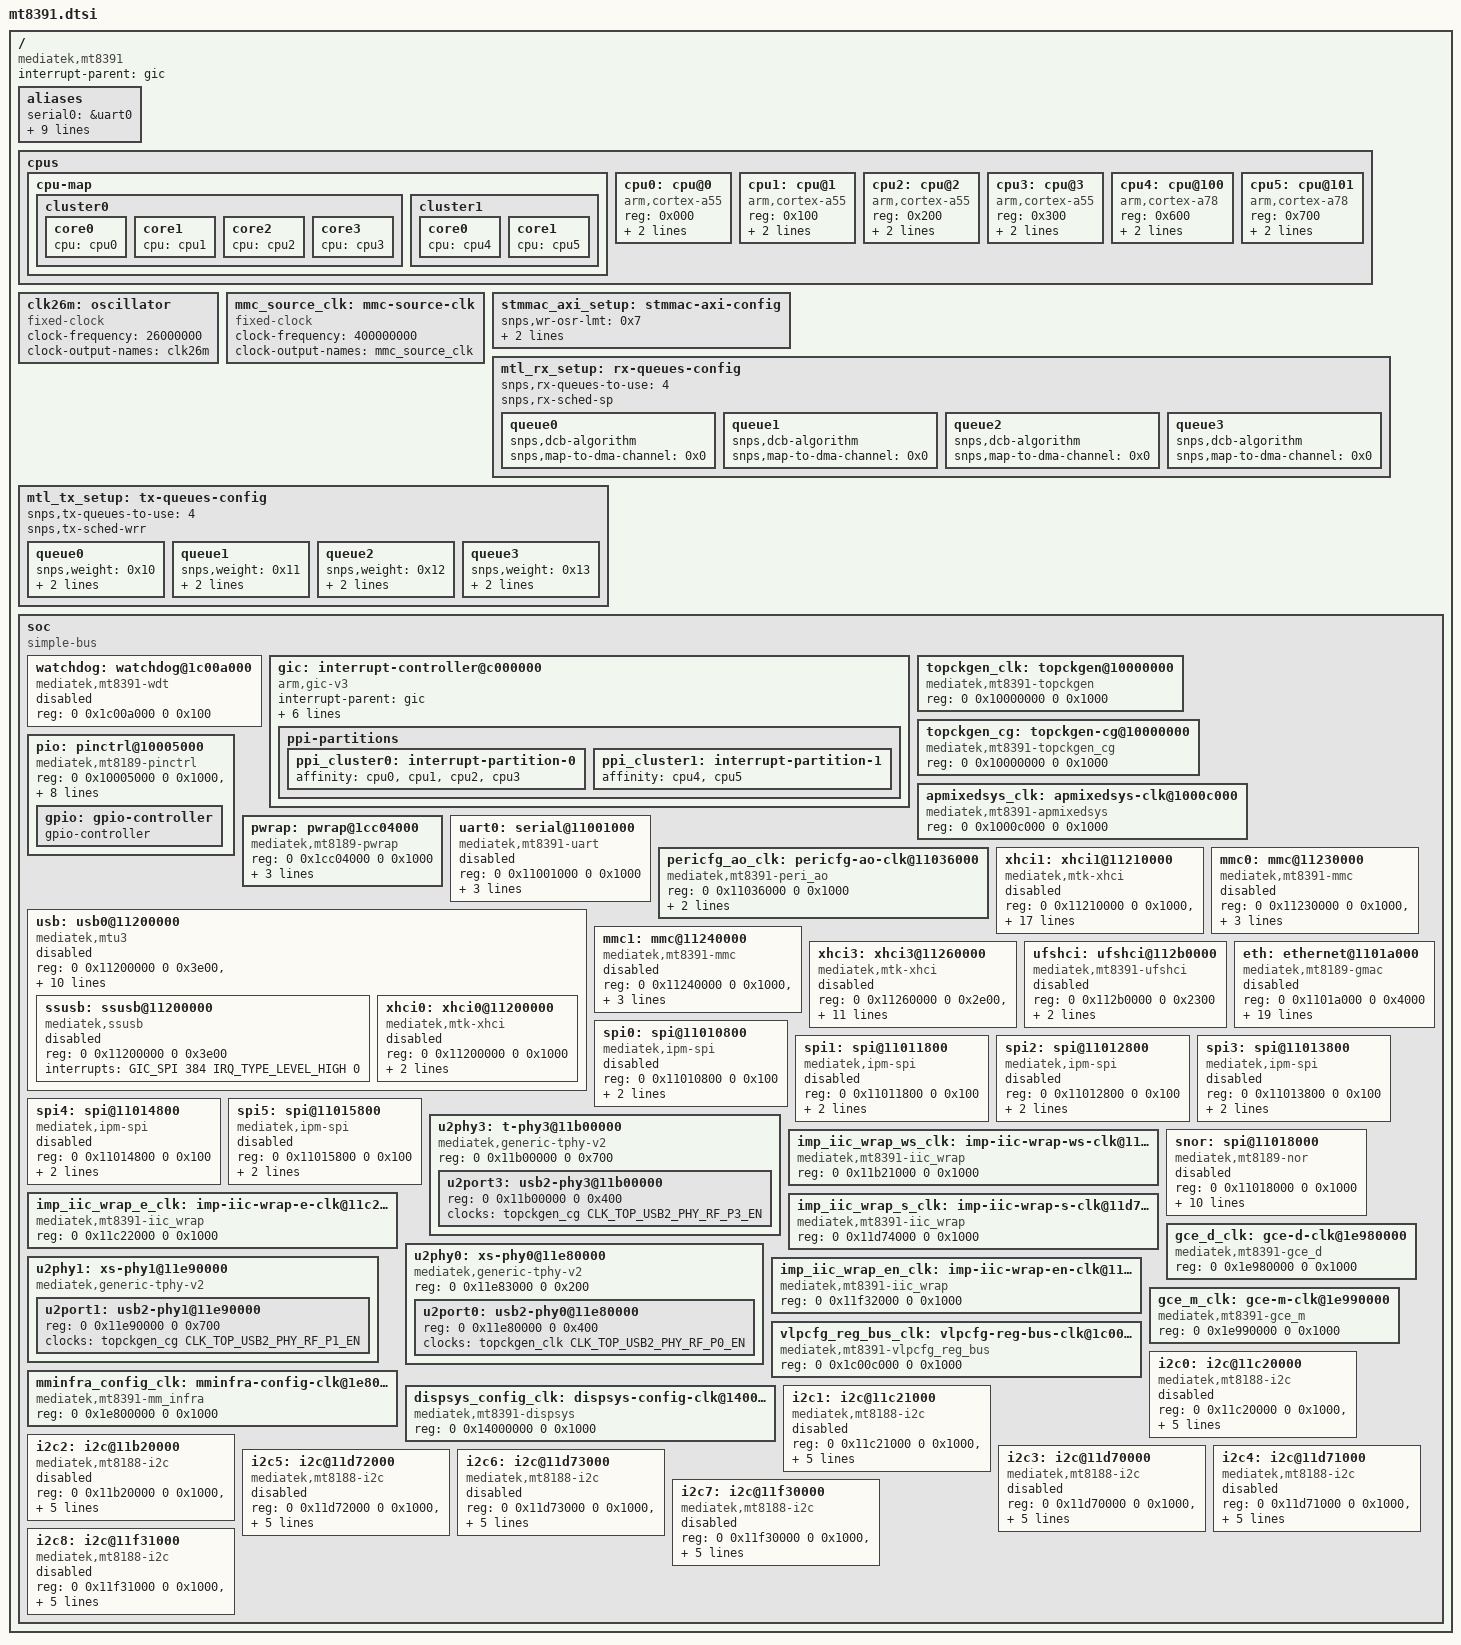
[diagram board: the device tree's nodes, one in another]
// SPDX-License-Identifier: (GPL-2.0 OR MIT)
/*
 * Copyright (C) 2023 MediaTek Inc.
 * Author: Macpaul Lin <macpaul.lin@mediatek.com>
 */

#include <dt-bindings/gpio/gpio.h>
#include <dt-bindings/interrupt-controller/irq.h>
#include <dt-bindings/interrupt-controller/arm-gic.h>
#include <dt-bindings/pinctrl/mediatek,mt8189-pinfunc.h>
#include <dt-bindings/phy/phy.h>
#include <dt-bindings/clock/mt8391-clk.h>

/ {
	compatible = "mediatek,mt8391";
	interrupt-parent = <&gic>;
	#address-cells = <2>;
	#size-cells = <2>;

	aliases {
		serial0 = &uart0;
		i2c0 = &i2c0;
		i2c1 = &i2c1;
		i2c2 = &i2c2;
		i2c3 = &i2c3;
		i2c4 = &i2c4;
		i2c5 = &i2c5;
		i2c6 = &i2c6;
		i2c7 = &i2c7;
		i2c8 = &i2c8;
	};

	cpus {
		#address-cells = <1>;
		#size-cells = <0>;

		cpu-map {
			cluster0 {
				core0 {
					cpu = <&cpu0>;
				};
				core1 {
					cpu = <&cpu1>;
				};
				core2 {
					cpu = <&cpu2>;
				};
				core3 {
					cpu = <&cpu3>;
				};
			};
			cluster1 {
				core0 {
					cpu = <&cpu4>;
				};
				core1 {
					cpu = <&cpu5>;
				};
			};
		};

		cpu0: cpu@0 {
			device_type = "cpu";
			compatible = "arm,cortex-a55", "arm,armv8";
			reg = <0x000>;
			enable-method = "psci";
			capacity-dmips-mhz = <282>;
		};

		cpu1: cpu@1 {
			device_type = "cpu";
			compatible = "arm,cortex-a55", "arm,armv8";
			reg = <0x100>;
			enable-method = "psci";
			capacity-dmips-mhz = <282>;
		};

		cpu2: cpu@2 {
			device_type = "cpu";
			compatible = "arm,cortex-a55", "arm,armv8";
			reg = <0x200>;
			enable-method = "psci";
			capacity-dmips-mhz = <282>;
		};

		cpu3: cpu@3 {
			device_type = "cpu";
			compatible = "arm,cortex-a55", "arm,armv8";
			reg = <0x300>;
			enable-method = "psci";
			capacity-dmips-mhz = <282>;
		};

		cpu4: cpu@100 {
			device_type = "cpu";
			compatible = "arm,cortex-a78", "arm,armv8";
			reg = <0x600>;
			enable-method = "psci";
			capacity-dmips-mhz = <1024>;
		};

		cpu5: cpu@101 {
			device_type = "cpu";
			compatible = "arm,cortex-a78", "arm,armv8";
			reg = <0x700>;
			enable-method = "psci";
			capacity-dmips-mhz = <1024>;
		};
	};

	clk26m: oscillator {
		compatible = "fixed-clock";
		#clock-cells = <0>;
		clock-frequency = <26000000>;
		clock-output-names = "clk26m";
	};

	mmc_source_clk: mmc-source-clk{
		compatible = "fixed-clock";
		#clock-cells = <0>;
		clock-frequency = <400000000>;
		clock-output-names = "mmc_source_clk";
	};

	stmmac_axi_setup: stmmac-axi-config {
		snps,wr-osr-lmt = <0x7>;
		snps,rd-osr-lmt = <0x7>;
		snps,blen = <0 0 0 0 16 8 4>;
	};

	mtl_rx_setup: rx-queues-config {
		snps,rx-queues-to-use = <4>;
		snps,rx-sched-sp;
		queue0 {
			snps,dcb-algorithm;
			snps,map-to-dma-channel = <0x0>;
		};
		queue1 {
			snps,dcb-algorithm;
			snps,map-to-dma-channel = <0x0>;
		};
		queue2 {
			snps,dcb-algorithm;
			snps,map-to-dma-channel = <0x0>;
		};
		queue3 {
			snps,dcb-algorithm;
			snps,map-to-dma-channel = <0x0>;
		};
	};

	mtl_tx_setup: tx-queues-config {
		snps,tx-queues-to-use = <4>;
		snps,tx-sched-wrr;
		queue0 {
			snps,weight = <0x10>;
			snps,dcb-algorithm;
			snps,priority = <0x0>;
		};
		queue1 {
			snps,weight = <0x11>;
			snps,dcb-algorithm;
			snps,priority = <0x1>;
		};
		queue2 {
			snps,weight = <0x12>;
			snps,dcb-algorithm;
			snps,priority = <0x2>;
		};
		queue3 {
			snps,weight = <0x13>;
			snps,dcb-algorithm;
			snps,priority = <0x3>;
		};
	};

	soc {
		#address-cells = <2>;
		#size-cells = <2>;
		compatible = "simple-bus";
		ranges;

		watchdog: watchdog@1c00a000 {
			compatible = "mediatek,mt8391-wdt",
				     "mediatek,wdt";
			reg = <0 0x1c00a000 0 0x100>;
			status = "disabled";
		};

		gic: interrupt-controller@c000000 {
			compatible = "arm,gic-v3";
			#interrupt-cells = <4>;
			interrupt-parent = <&gic>;
			interrupt-controller;
			reg = <0 0x0c000000 0 0x40000>,  /* GICD */
			      <0 0x0c100000 0 0x200000>, /* GICR */
			      <0 0x0c400000 0 0x2000>,   /* GICC */
			      <0 0x0c410000 0 0x1000>,   /* GICH */
			      <0 0x0c420000 0 0x2000>;   /* GICV */

			interrupts = <GIC_PPI 9 IRQ_TYPE_LEVEL_HIGH 0>;
			ppi-partitions {
				ppi_cluster0: interrupt-partition-0 {
					affinity = <&cpu0 &cpu1 &cpu2 &cpu3>;
				};
				ppi_cluster1: interrupt-partition-1 {
					affinity = <&cpu4 &cpu5>;
				};
			};
		};

		topckgen_clk: topckgen@10000000 {
			compatible = "mediatek,mt8391-topckgen";
			reg = <0 0x10000000 0 0x1000>;
			#clock-cells = <1>;
		};

		topckgen_cg: topckgen-cg@10000000 {
			compatible = "mediatek,mt8391-topckgen_cg";
			reg = <0 0x10000000 0 0x1000>;
			#clock-cells = <1>;
		};

		apmixedsys_clk: apmixedsys-clk@1000c000 {
			compatible = "mediatek,mt8391-apmixedsys";
			reg = <0 0x1000c000 0 0x1000>;
			#clock-cells = <1>;
		};

		pio: pinctrl@10005000 {
			compatible = "mediatek,mt8189-pinctrl";
			reg = <0 0x10005000 0 0x1000>,
				<0 0x11d20000 0 0x1000>,
				<0 0x11d30000 0 0x1000>,
				<0 0x11d40000 0 0x1000>,
				<0 0x11b50000 0 0x1000>,
				<0 0x11e20000 0 0x1000>,
				<0 0x11e30000 0 0x1000>,
				<0 0x11c50000 0 0x1000>,
				<0 0x11c60000 0 0x1000>,
				<0 0x11f20000 0 0x1000>;
			reg-names = "gpio_base",
				"iocfg_bm0_base",
				"iocfg_bm1_base",
				"iocfg_bm2_base",
				"iocfg_lm_base",
				"iocfg_lt0_base",
				"iocfg_lt1_base",
				"iocfg_rb0_base",
				"iocfg_rb1_base",
				"iocfg_rt_base";
			gpio: gpio-controller {
				gpio-controller;
				#gpio-cells = <2>;
			};
		};

		pwrap: pwrap@1cc04000 {
			compatible = "mediatek,mt8189-pwrap";
			reg = <0 0x1cc04000 0 0x1000>;
			clocks =  <&vlpcfg_reg_bus_clk CLK_VLPCFG_REG_PMIF_SPMI_M_SYS>,
				<&vlpcfg_reg_bus_clk CLK_VLPCFG_REG_PMIF_SPMI_M_TMR>;
			clock-names = "spi", "wrap";
		};

		uart0: serial@11001000 {
			compatible = "mediatek,mt8391-uart",
				     "mediatek,hsuart";
			reg = <0 0x11001000 0 0x1000>;
			interrupts = <GIC_SPI 91 IRQ_TYPE_LEVEL_LOW>;
			clock-frequency = <26000000>;
			clocks = <&clk26m>, <&clk26m>;
			clock-names = "baud", "bus";
			status = "disabled";
		};

		pericfg_ao_clk: pericfg-ao-clk@11036000 {
			compatible = "mediatek,mt8391-peri_ao", "syscon";
			reg = <0 0x11036000 0 0x1000>;
			#clock-cells = <1>;
			clocks = <&topckgen_clk>;
			clock-output-names = "pericfg_ao_clk";
		};

		usb: usb0@11200000 {
			compatible = "mediatek,mtu3";
			reg = <0 0x11200000 0 0x3e00>,
			      <0 0x11203e00 0 0x0100>;
			reg-names = "mac", "ippc";
			phy-cells = <1>;
			phys = <&u2port0 PHY_TYPE_USB2>;
			mediatek,u3p-dis-msk = <0x1>;
			clocks = <&pericfg_ao_clk CLK_PERAO_SSUSB0_XHCI>,
				 <&pericfg_ao_clk CLK_PERAO_SSUSB0_SYS>,
				 <&pericfg_ao_clk CLK_PERAO_SSUSB0_H>,
				 <&pericfg_ao_clk CLK_PERAO_SSUSB0_F>,
				 <&pericfg_ao_clk CLK_PERAO_SSUSB0_REF>,
				 <&pericfg_ao_clk CLK_PERAO_SSUSB0_FRMCNT>;
			clock-names = "host_ck",
				      "sys_ck",
				      "mcu_ck",
				      "dma_ck",
				      "ref_ck",
				      "frmcnt_ck";
			#address-cells = <2>;
			#size-cells = <2>;
			ranges;
			status = "disabled";

			ssusb: ssusb@11200000 {
				compatible = "mediatek,ssusb";
				reg = <0 0x11200000 0 0x3e00>;
				reg-names = "mac";
				interrupts = <GIC_SPI 384 IRQ_TYPE_LEVEL_HIGH 0>;
				status = "disabled";
			};

			xhci0: xhci0@11200000 {
				compatible = "mediatek,mtk-xhci";
				reg = <0 0x11200000 0 0x1000>;
				reg-names = "mac";
				interrupts = <GIC_SPI 385 IRQ_TYPE_LEVEL_HIGH 0>;
				clocks = <&pericfg_ao_clk CLK_PERAO_SSUSB0_XHCI>;
				clock-names = "xhci_ck";
				status = "disabled";
			};
		};

		xhci1: xhci1@11210000 {
			compatible = "mediatek,mtk-xhci";
			reg = <0 0x11210000 0 0x1000>,
			      <0 0x11213e00 0 0x0100>;
			reg-names = "mac", "ippc";
			interrupts = <GIC_SPI 386 IRQ_TYPE_LEVEL_HIGH 0>;
			phy-cells = <1>;
			phys = <&u2port1 PHY_TYPE_USB2>;
			assigned-clocks = <&topckgen_clk CLK_TOP_USB_TOP_P1_SEL>,
					  <&topckgen_clk CLK_TOP_USB_XHCI_P1_SEL>;
			assigned-clock-parents = <&topckgen_clk CLK_TOP_UNIVPLL_D5_D4>,
						 <&topckgen_clk CLK_TOP_UNIVPLL_D5_D4>;
			clocks = <&pericfg_ao_clk CLK_PERAO_SSUSB1_XHCI>,
				 <&pericfg_ao_clk CLK_PERAO_SSUSB1_SYS>,
				 <&pericfg_ao_clk CLK_PERAO_SSUSB1_H>,
				 <&pericfg_ao_clk CLK_PERAO_SSUSB1_F>,
				 <&pericfg_ao_clk CLK_PERAO_SSUSB1_REF>,
				 <&pericfg_ao_clk CLK_PERAO_SSUSB1_FRMCNT>;
			clock-names = "xhci_ck",
				      "sys_ck",
				      "mcu_ck",
				      "dma_ck",
				      "ref_ck",
				      "frmcnt_ck";
			maximum-speed = "high-speed";
			status = "disabled";
		};

		mmc0: mmc@11230000 {
			compatible = "mediatek,mt8391-mmc",
				     "mediatek,mt8183-mmc";
			reg = <0 0x11230000 0 0x1000>,
			      <0 0x11e70000 0 0x1000>;
			interrupts = <GIC_SPI 387 IRQ_TYPE_LEVEL_HIGH 0>;
			clocks = <&mmc_source_clk>,
				 <&clk26m>,
				 <&clk26m>;
			clock-names = "source", "hclk", "source_cg";
			status = "disabled";
		};

		mmc1: mmc@11240000 {
			compatible = "mediatek,mt8391-mmc",
				     "mediatek,mt8183-mmc";
			reg = <0 0x11240000 0 0x1000>,
			      <0 0x11d80000 0 0x1000>;
			interrupts = <GIC_SPI 388 IRQ_TYPE_LEVEL_HIGH 0>;
			clocks = <&mmc_source_clk>,
				 <&clk26m>,
				 <&clk26m>;
			clock-names = "source", "hclk", "source_cg";
			status = "disabled";
		};

		xhci3: xhci3@11260000 {
			compatible = "mediatek,mtk-xhci";
			reg = <0 0x11260000 0 0x2e00>,
			      <0 0x11263e00 0 0x0100>;
			reg-names = "mac", "ippc";
			interrupts = <GIC_SPI 473 IRQ_TYPE_LEVEL_HIGH 0>;
			phy-cells = <1>;
			phys = <&u2port3 PHY_TYPE_USB2>;
			mediatek,u3p-dis-msk = <0x1>;
			clocks = <&pericfg_ao_clk CLK_PERAO_SSUSB3_XHCI>,
				 <&pericfg_ao_clk CLK_PERAO_SSUSB3_SYS>,
				 <&pericfg_ao_clk CLK_PERAO_SSUSB3_H>,
				 <&pericfg_ao_clk CLK_PERAO_SSUSB3_F>,
				 <&pericfg_ao_clk CLK_PERAO_SSUSB3_REF>,
				 <&pericfg_ao_clk CLK_PERAO_SSUSB3_FRMCNT>;
			clock-names = "xhci_ck",
				      "sys_ck",
				      "mcu_ck",
				      "dma_ck",
				      "ref_ck",
				      "frmcnt_ck";
			status = "disabled";
		};

		ufshci: ufshci@112b0000 {
			compatible = "mediatek,mt8391-ufshci",
				     "mediatek,mt8183-ufshci";
			reg = <0 0x112b0000 0 0x2300>;
			interrupts = <GIC_SPI 393 IRQ_TYPE_LEVEL_HIGH 0>;
			clocks = <&mmc_source_clk>,
				 <&clk26m>,
				 <&clk26m>;
			clock-names = "source", "hclk", "source_cg";
			status = "disabled";
		};

		eth: ethernet@1101a000 {
			compatible = "mediatek,mt8189-gmac", "snps,dwmac-5.10a";
			reg = <0 0x1101a000 0 0x4000>;
			interrupts = <GIC_SPI 475 IRQ_TYPE_LEVEL_HIGH 0>;
			interrupt-names = "macirq";
			clock-names = "mac_main",
					"ptp_ref",
					"rmii_internal";
			clocks = <&topckgen_clk CLK_TOP_ETH_250M_SEL>,
				<&topckgen_clk CLK_TOP_ETH_62P4M_PTP_SEL>,
				<&topckgen_clk CLK_TOP_ETH_50M_RMII_SEL>;
			assigned-clocks = <&topckgen_clk CLK_TOP_ETH_250M_SEL>,
				  <&topckgen_clk CLK_TOP_ETH_62P4M_PTP_SEL>,
				  <&topckgen_clk CLK_TOP_ETH_50M_RMII_SEL>;
			assigned-clock-parents = <&topckgen_clk CLK_TOP_ETHPLL_D2>,
						<&topckgen_clk CLK_TOP_ETHPLL_D8>,
						<&topckgen_clk CLK_TOP_ETHPLL_D10>;
			mediatek,pericfg = <&pericfg_ao_clk>;
			snps,axi-config = <&stmmac_axi_setup>;
			snps,mtl-rx-config = <&mtl_rx_setup>;
			snps,mtl-tx-config = <&mtl_tx_setup>;
			snps,txpbl = <16>;
			snps,rxpbl = <16>;
			clk-csr = <4>;
			status = "disabled";
		};

		spi0: spi@11010800 {
			compatible = "mediatek,ipm-spi";
			reg = <0 0x11010800 0 0x100>;
			interrupts = <GIC_SPI 459 IRQ_TYPE_LEVEL_HIGH>;
			clocks = <&pericfg_ao_clk CLK_PERAO_SPI0_B>;
			clock-names = "spi-clk";
			status = "disabled";
		};

		spi1: spi@11011800 {
			compatible = "mediatek,ipm-spi";
			reg = <0 0x11011800 0 0x100>;
			interrupts = <GIC_SPI 460 IRQ_TYPE_LEVEL_HIGH>;
			clocks = <&pericfg_ao_clk CLK_PERAO_SPI1_B>;
			clock-names = "spi-clk";
			status = "disabled";
		};

		spi2: spi@11012800 {
			compatible = "mediatek,ipm-spi";
			reg = <0 0x11012800 0 0x100>;
			interrupts = <GIC_SPI 461 IRQ_TYPE_LEVEL_HIGH>;
			clocks = <&pericfg_ao_clk CLK_PERAO_SPI2_B>;
			clock-names = "spi-clk";
			status = "disabled";
		};

		spi3: spi@11013800 {
			compatible = "mediatek,ipm-spi";
			reg = <0 0x11013800 0 0x100>;
			interrupts = <GIC_SPI 462 IRQ_TYPE_LEVEL_HIGH>;
			clocks = <&pericfg_ao_clk CLK_PERAO_SPI3_B>;
			clock-names = "spi-clk";
			status = "disabled";
		};

		spi4: spi@11014800 {
			compatible = "mediatek,ipm-spi";
			reg = <0 0x11014800 0 0x100>;
			interrupts = <GIC_SPI 463 IRQ_TYPE_LEVEL_HIGH>;
			clocks = <&pericfg_ao_clk CLK_PERAO_SPI4_B>;
			clock-names = "spi-clk";
			status = "disabled";
		};

		spi5: spi@11015800 {
			compatible = "mediatek,ipm-spi";
			reg = <0 0x11015800 0 0x100>;
			interrupts = <GIC_SPI 464 IRQ_TYPE_LEVEL_HIGH>;
			clocks = <&pericfg_ao_clk CLK_PERAO_SPI5_B>;
			clock-names = "spi-clk";
			status = "disabled";
		};

		u2phy3: t-phy3@11b00000 {
			compatible = "mediatek,generic-tphy-v2";
			reg = <0 0x11b00000 0 0x700>;
			#address-cells = <2>;
			#size-cells = <2>;
			ranges;

			u2port3: usb2-phy3@11b00000 {
				reg = <0 0x11b00000 0 0x400>;
				clocks = <&topckgen_cg CLK_TOP_USB2_PHY_RF_P3_EN>;
				clock-names = "ref";
				#phy-cells = <1>;
			};
		};

		imp_iic_wrap_ws_clk: imp-iic-wrap-ws-clk@11b21000 {
			compatible = "mediatek,mt8391-iic_wrap";
			reg = <0 0x11b21000 0 0x1000>;
			#clock-cells = <1>;
		};

		imp_iic_wrap_e_clk: imp-iic-wrap-e-clk@11c22000 {
			compatible = "mediatek,mt8391-iic_wrap";
			reg = <0 0x11c22000 0 0x1000>;
			#clock-cells = <1>;
		};

		imp_iic_wrap_s_clk: imp-iic-wrap-s-clk@11d74000 {
			compatible = "mediatek,mt8391-iic_wrap";
			reg = <0 0x11d74000 0 0x1000>;
			#clock-cells = <1>;
		};

		u2phy0: xs-phy0@11e80000 {
			compatible = "mediatek,generic-tphy-v2";
			reg = <0 0x11e83000 0 0x200>;
			#address-cells = <2>;
			#size-cells = <2>;
			ranges;

			u2port0: usb2-phy0@11e80000 {
				reg = <0 0x11e80000 0 0x400>;
				clocks = <&topckgen_clk CLK_TOP_USB2_PHY_RF_P0_EN>;
				clock-names = "ref";
				#phy-cells = <1>;
			};
		};

		u2phy1: xs-phy1@11e90000 {
			compatible = "mediatek,generic-tphy-v2";
			#address-cells = <2>;
			#size-cells = <2>;
			ranges;

			u2port1: usb2-phy1@11e90000 {
				reg = <0 0x11e90000 0 0x700>;
				clocks = <&topckgen_cg CLK_TOP_USB2_PHY_RF_P1_EN>;
				clock-names = "ref";
				#phy-cells = <1>;
			};
		};

		snor: spi@11018000 {
			compatible = "mediatek,mt8189-nor";
			reg = <0 0x11018000 0 0x1000>;
			clocks = <&topckgen_clk CLK_TOP_SFLASH_SEL>,
				<&pericfg_ao_clk CLK_PERAO_SFLASH>,
				<&pericfg_ao_clk CLK_PERAO_SFLASH_F>,
				<&pericfg_ao_clk CLK_PERAO_SFLASH_H>,
				<&pericfg_ao_clk CLK_PERAO_SFLASH_P>;
			clock-names = "spi", "sf", "axi_f", "axi_h", "axi_p";
			assigned-clocks = <&topckgen_clk CLK_TOP_SFLASH_SEL>;
			assigned-clock-parents = <&topckgen_clk CLK_TOP_UNIVPLL_D6_D8>;
			interrupts = <GIC_SPI 390 IRQ_TYPE_LEVEL_HIGH 0>;
			#address-cells = <1>;
			#size-cells = <0>;
			status = "disabled";
		};

		imp_iic_wrap_en_clk: imp-iic-wrap-en-clk@11f32000 {
			compatible = "mediatek,mt8391-iic_wrap";
			reg = <0 0x11f32000 0 0x1000>;
			#clock-cells = <1>;
		};

		vlpcfg_reg_bus_clk: vlpcfg-reg-bus-clk@1c00c000 {
			compatible = "mediatek,mt8391-vlpcfg_reg_bus";
			reg = <0 0x1c00c000 0 0x1000>;
			#clock-cells = <1>;
		};

		mminfra_config_clk: mminfra-config-clk@1e800000 {
			compatible = "mediatek,mt8391-mm_infra";
			reg = <0 0x1e800000 0 0x1000>;
			#clock-cells = <1>;
		};

		gce_d_clk: gce-d-clk@1e980000 {
			compatible = "mediatek,mt8391-gce_d";
			reg = <0 0x1e980000 0 0x1000>;
			#clock-cells = <1>;
		};

		gce_m_clk: gce-m-clk@1e990000 {
			compatible = "mediatek,mt8391-gce_m";
			reg = <0 0x1e990000 0 0x1000>;
			#clock-cells = <1>;
		};

		dispsys_config_clk: dispsys-config-clk@14000000 {
			compatible = "mediatek,mt8391-dispsys";
			reg = <0 0x14000000 0 0x1000>;
			#clock-cells = <1>;
		};

		i2c0: i2c@11c20000 {
			compatible = "mediatek,mt8188-i2c";
			reg = <0 0x11c20000 0 0x1000>,
				<0 0x11300200 0 0x80>;
			interrupts = <GIC_SPI 274 IRQ_TYPE_LEVEL_HIGH 0>;
			clocks = <&imp_iic_wrap_e_clk CLK_IMPE_I2C0>,
				<&pericfg_ao_clk CLK_PERAO_DMA_B>;
			clock-names = "main", "dma";
			clock-div = <1>;
			#address-cells = <1>;
			#size-cells = <0>;
			status = "disabled";
		};

		i2c1: i2c@11c21000 {
			compatible = "mediatek,mt8188-i2c";
			reg = <0 0x11c21000 0 0x1000>,
				<0 0x11300300 0 0x80>;
			interrupts = <GIC_SPI 275 IRQ_TYPE_LEVEL_HIGH 0>;
			clocks = <&imp_iic_wrap_e_clk CLK_IMPE_I2C1>,
				<&pericfg_ao_clk CLK_PERAO_DMA_B>;
			clock-names = "main", "dma";
			clock-div = <1>;
			#address-cells = <1>;
			#size-cells = <0>;
			status = "disabled";
		};

		i2c2: i2c@11b20000 {
			compatible = "mediatek,mt8188-i2c";
			reg = <0 0x11b20000 0 0x1000>,
				<0 0x11300400 0 0x80>;
			interrupts = <GIC_SPI 276 IRQ_TYPE_LEVEL_HIGH 0>;
			clocks = <&imp_iic_wrap_ws_clk CLK_IMPWS_I2C2>,
				<&pericfg_ao_clk CLK_PERAO_DMA_B>;
			clock-names = "main", "dma";
			clock-div = <1>;
			#address-cells = <1>;
			#size-cells = <0>;
			status = "disabled";
		};

		i2c3: i2c@11d70000 {
			compatible = "mediatek,mt8188-i2c";
			#address-cells = <1>;
			#size-cells = <0>;
			reg = <0 0x11d70000 0 0x1000>,
				<0 0x11300500 0 0x80>;
			interrupts = <GIC_SPI 277 IRQ_TYPE_LEVEL_HIGH 0>;
			clocks = <&imp_iic_wrap_s_clk CLK_IMPS_I2C3>,
				<&pericfg_ao_clk CLK_PERAO_DMA_B>;
			clock-names = "main", "dma";
			clock-div = <1>;
			status = "disabled";
		};

		i2c4: i2c@11d71000 {
			compatible = "mediatek,mt8188-i2c";
			reg = <0 0x11d71000 0 0x1000>,
				<0 0x11300600 0 0x80>;
			interrupts = <GIC_SPI 208 IRQ_TYPE_LEVEL_HIGH 0>;
			clocks = <&imp_iic_wrap_s_clk CLK_IMPS_I2C4>,
				<&pericfg_ao_clk CLK_PERAO_DMA_B>;
			clock-names = "main", "dma";
			clock-div = <1>;
			#address-cells = <1>;
			#size-cells = <0>;
			status = "disabled";
		};

		i2c5: i2c@11d72000 {
			compatible = "mediatek,mt8188-i2c";
			#address-cells = <1>;
			#size-cells = <0>;
			reg = <0 0x11d72000 0 0x1000>,
				<0 0x11300700 0 0x80>;
			interrupts = <GIC_SPI 209 IRQ_TYPE_LEVEL_HIGH 0>;
			clocks = <&imp_iic_wrap_s_clk CLK_IMPS_I2C5>,
				<&pericfg_ao_clk CLK_PERAO_DMA_B>;
			clock-names = "main", "dma";
			clock-div = <1>;
			status = "disabled";
		};

		i2c6: i2c@11d73000 {
			compatible = "mediatek,mt8188-i2c";
			#address-cells = <1>;
			#size-cells = <0>;
			reg = <0 0x11d73000 0 0x1000>,
				<0 0x11300800 0 0x80>;
			interrupts = <GIC_SPI 210 IRQ_TYPE_LEVEL_HIGH 0>;
			clocks = <&imp_iic_wrap_s_clk CLK_IMPS_I2C6>,
				<&pericfg_ao_clk CLK_PERAO_DMA_B>;
			clock-names = "main", "dma";
			clock-div = <1>;
			status = "disabled";
		};

		i2c7: i2c@11f30000 {
			compatible = "mediatek,mt8188-i2c";
			reg = <0 0x11f30000 0 0x1000>,
				<0 0x11300900 0 0x80>;
			interrupts = <GIC_SPI 211 IRQ_TYPE_LEVEL_HIGH 0>;
			clocks = <&imp_iic_wrap_en_clk CLK_IMPEN_I2C7>,
				<&pericfg_ao_clk CLK_PERAO_DMA_B>;
			clock-names = "main", "dma";
			clock-div = <1>;
			#address-cells = <1>;
			#size-cells = <0>;
			status = "disabled";
		};

		i2c8: i2c@11f31000 {
			compatible = "mediatek,mt8188-i2c";
			reg = <0 0x11f31000 0 0x1000>,
				<0 0x11300a00 0 0x80>;
			interrupts = <GIC_SPI 212 IRQ_TYPE_LEVEL_HIGH 0>;
			clocks = <&imp_iic_wrap_en_clk CLK_IMPEN_I2C8>,
				<&pericfg_ao_clk CLK_PERAO_DMA_B>;
			clock-names = "main", "dma";
			clock-div = <1>;
			#address-cells = <1>;
			#size-cells = <0>;
			status = "disabled";
		};
	};
};
